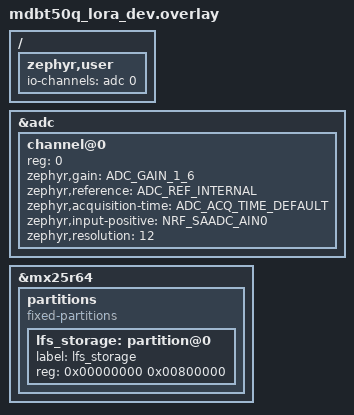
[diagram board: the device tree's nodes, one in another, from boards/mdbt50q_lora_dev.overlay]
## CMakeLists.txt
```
cmake_minimum_required(VERSION 3.20.0)

find_package(Zephyr REQUIRED HINTS $ENV{ZEPHYR_BASE})
project(6sens_rtos_store)

FILE(GLOB app_sources src/*.c)
target_sources(app PRIVATE ${app_sources})
```

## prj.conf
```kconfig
# Debugger Support
CONFIG_UART_CONSOLE=n
CONFIG_CONSOLE=y
CONFIG_SERIAL=y

# RTT Segger Support
CONFIG_RTT_CONSOLE=y
CONFIG_USE_SEGGER_RTT=y
CONFIG_LOG_BACKEND_RTT=y

# Communication Bus Support
CONFIG_GPIO=y
CONFIG_SPI=y

# Hardware Support
CONFIG_ADC=y
CONFIG_RING_BUFFER=y

# Flash Memory Support (MX25R64)
CONFIG_FLASH=y
CONFIG_FLASH_MAP=y
CONFIG_MPU_ALLOW_FLASH_WRITE=y
CONFIG_NORDIC_QSPI_NOR=y

# File System Support
CONFIG_FILE_SYSTEM=y
CONFIG_FILE_SYSTEM_LITTLEFS=y

# Threads Support
CONFIG_MAIN_STACK_SIZE=4096

# Utils
CONFIG_BASE64=y
```

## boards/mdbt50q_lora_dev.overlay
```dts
/*
 * Copyright (c) 2025
 * Regis Rousseau
 * Univ Lyon, INSA Lyon, Inria, CITI, EA3720
 * SPDX-License-Identifier: Apache-2.0
 */

/* Sismic sensor analog value conversion */
/* external ADC channnel of MDBT50Q, Port P0.02 on schematic */
/ {
	zephyr,user {
		io-channels = <&adc 0>;
	};
};

/* enable the corresponding ADC, with the correct configuration */
&adc {
	#address-cells	= <1>;
	#size-cells 	= <0>;
	status			= "okay";
	channel@0 {
		reg 					= <0>;						/* channel 0 of the ADC */
		zephyr,gain				= "ADC_GAIN_1_6";			/* attenuated by 6 (x1/6) */
		zephyr,reference		= "ADC_REF_INTERNAL";		/* reference voltage +0.6 */
		zephyr,acquisition-time = <ADC_ACQ_TIME_DEFAULT>;	/* 10us */
		zephyr,input-positive	= <NRF_SAADC_AIN0>;			/* P0.02 for nRF52xx */
		zephyr,resolution		= <12>;
	};
};

&mx25r64 {
	partitions {
		compatible		= "fixed-partitions";
		#address-cells	= <1>;
		#size-cells		= <1>;

		lfs_storage: partition@0 {
			label	= "lfs_storage";
			reg		= <0x00000000 0x00800000>;
		};
	};
};
```

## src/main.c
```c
/*
 * Copyright (c) 2025
 * Regis Rousseau
 * Univ Lyon, INSA Lyon, Inria, CITI, EA3720
 * SPDX-License-Identifier: Apache-2.0
 */

//  ========== includes ====================================================================
#include "app_adc.h"
#include "app_storage.h"
#include "fs_utils.h"

//  ========== defines =====================================================================
#define STACK_SIZE 					4096
#define ADC_THREAD_PRIORITY 		2
#define STORAGE_THREAD_PRIORITY		3
RING_BUF_DECLARE(adc_ringbuf, BUFFER_SIZE_SAMPLES * SAMPLE_SIZE_BYTES);

//  ========== globals =====================================================================
K_THREAD_STACK_DEFINE(adc_stack, STACK_SIZE);
K_THREAD_STACK_DEFINE(storage_stack, STACK_SIZE);

static struct k_thread adc_thread_data;
static struct k_thread storage_thread_data;

// ========== main =========================================================================
int main(void)
{	
	// initialize ADC device
	int8_t ret = app_nrf52_adc_init();
	if (ret != 1) {
		printk("failed to initialize ADC device\n");
		return 0;
	}

	printk("Geophone Acquisition Example\n");
	
	int rc = mount_lfs();
	if (rc < 0) {
        printk("mount failed. stopping application: %d\n", rc);
        return rc;
    }
	int clean_fs = false;
	// Dump the content of /lfs filesystem
	dump_fs(clean_fs);
    // start threads
    k_thread_create(&adc_thread_data, adc_stack, STACK_SIZE,
                    (k_thread_entry_t)app_nrf52_adc_thread, NULL, NULL, NULL,
                    ADC_THREAD_PRIORITY, 0, K_NO_WAIT);

    k_thread_create(&storage_thread_data, storage_stack, STACK_SIZE,
                    (k_thread_entry_t)app_storage_thread, NULL, NULL, NULL,
                    STORAGE_THREAD_PRIORITY, 0, K_NO_WAIT);

	while (1) {
        k_sleep(K_SECONDS(5));
	}
	return 0;
}
```

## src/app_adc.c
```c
/*
 * Copyright (c) 2025
 * Regis Rousseau
 * Univ Lyon, INSA Lyon, Inria, CITI, EA3720
 * SPDX-License-Identifier: Apache-2.0
 */

//  ========== includes ====================================================================
#include "app_adc.h"

//  ========== globals =====================================================================
// ADC buffer to store raw ADC readings
int16_t buf;

// ADC channel configuration obtained from the device tree
static const struct adc_dt_spec adc_channel = ADC_DT_SPEC_GET(DT_PATH(zephyr_user));

// ADC sequence configuration to specify the ADC operation
static struct adc_sequence sequence = {
    .channels = 0,
	.buffer = &buf,
	.buffer_size = sizeof(buf),
};

//  ========== app_nrf52_adc_init ==========================================================
int8_t app_nrf52_adc_init()
{
    int8_t ret;

    // verify if the ADC is ready for operation
    if (!adc_is_ready_dt(&adc_channel)) {
		printk("ADC is not ready\n");
		return 0;
    }
    
    // configure the ADC channel settings
    ret = adc_channel_setup_dt(&adc_channel);
	if (ret < 0) {
		printk("failed to set up ADC channel. error: %d\n", ret);
		return 0;
	}

    // initialize the ADC sequence for continuous or single readings
    ret = adc_sequence_init_dt(&adc_channel, &sequence);
	if (ret < 0) {
		printk("failed to initialize ADC sequence. error: %d\n", ret);
		return 0;
	}
    return 1;
}

//  ========== app_nrf52_get_adc ===========================================================
int16_t app_nrf52_adc_get()
{
    int16_t velocity;       // converted voltage value in mV
    int8_t ret;
    
    // trigger an ADC read and store the result in the configured buffer
    ret = adc_read(adc_channel.dev, &sequence);
    if (ret < 0) {        
	    printk("failed to read raw ADC value. error: %d\n", ret);
	    return 0;
    }

    //printk("raw adc value: %d\n", buf);

    // convert the raw ADC reading into a voltage value (in millivolts)
    velocity = (buf * ADC_FULL_SCALE_MV) / ADC_RESOLUTION;
    //printk("velocity: %d mV\n", velocity);
    return (int16_t)velocity;
}

//  ========== app_nrf52_adc_thread ========================================================
void app_nrf52_adc_thread(void *a, void *b, void *c)
{
    uint64_t next = k_uptime_get();
    
    while (1) {
        int16_t sample = app_nrf52_adc_get();

        uint32_t written = ring_buf_put(&adc_ringbuf, (uint8_t *)&sample, sizeof(sample));
           if (written < sizeof(sample)) {
            //printk("ring buffer full, dropping sample\n");
        }

        next += SAMPLE_RATE_MS;
        int64_t now = k_uptime_get();
        if (next > now) {
            k_sleep(K_MSEC(next - now));
        } else {
            next = now;
        }
    }
}
```

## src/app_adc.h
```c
/*
 * Copyright (c) 2025
 * Regis Rousseau
 * Univ Lyon, INSA Lyon, Inria, CITI, EA3720
 * SPDX-License-Identifier: Apache-2.0
 */

#ifndef APP_ADC_H
#define APP_ADC_H

//  ========== includes ====================================================================
#include <zephyr/kernel.h>
#include <zephyr/device.h>
#include <zephyr/devicetree.h>
#include <zephyr/drivers/adc.h>
#include <zephyr/sys/ring_buffer.h> 

//  ========== defines =====================================================================
// ADC characteristics (nRF52 SAADC)
#define ADC_REF_INTERNAL_MV         600     // 0.6 V internal reference
#define ADC_GAIN                    6       // using ADC_GAIN_1_6 -> 1/6
#define ADC_RESOLUTION              4096    // 12-bit

// effective full-scale voltage in mV
#define ADC_FULL_SCALE_MV   ((ADC_REF_INTERNAL_MV * ADC_GAIN))  // 3600 mV full scale

#define SAMPLE_RATE_MS              10
#define BUFFER_SIZE_SAMPLES         512
#define SAMPLE_SIZE_BYTES           sizeof(int16_t)

//  ========== globals =====================================================================
extern struct ring_buf adc_ringbuf;

//  ========== prototypes ==================================================================
int8_t app_nrf52_adc_init();
int16_t app_nrf52_adc_get();
void app_nrf52_adc_thread();

#endif /* APP_ADC_H */
```

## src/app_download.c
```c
/*
 * Copyright (c) 2025
 * Hugo Reymond, Regis Rousseau
 * Univ Lyon, INSA Lyon, Inria, CITI, EA3720
 * SPDX-License-Identifier: Apache-2.0
 */
#include "app_download.h"
#include <zephyr/sys/base64.h>
//  ========== globals =====================================================================
char ram_buffer[DOWNLOAD_RAM_BUF_SIZE];

//  ========== setup_download() ============================================================
void setup_download()
{
    int not_found = 1;
    int rc = 0;

    // Check if flash has been mounted
    while (not_found)
    {
        int mount_index = 0;
        char name[30];
        char *new_name = name;
        rc = 0;
        while (rc == 0)
        {
            rc = fs_readmount(&mount_index, &new_name);
            if (new_name[0] != 0)
            {
                printk("Found mount : %s\n", new_name);
            }
            if (new_name[0] == '/' && new_name[1] == 'l' && new_name[2] == 'f' && new_name[3] == 's')
            {
                printk("LFS mount is here !\n");
                not_found = 0;
            }
        }
        if (not_found)
        {
            printk("LFS mount not found,  sleeping...\n");
            k_sleep(K_SECONDS(1));
        }
    }

    // Get the lfs folder
    struct fs_dir_t root_dir;
    fs_dir_t_init(&root_dir);
    rc = fs_opendir(&root_dir, "/lfs");
    switch (rc)
    {
    case -EINVAL:
        printk("Bad directory given...\n");
        break;
    case 0:
        printk("Opened root folder\n");
    default:
        break;
        printk("Error : error code=%d\n", rc);
    }

    printk("Reading content of lfs dir\n");
    struct fs_dirent dir_entry;
    while (true)
    {
        rc = fs_readdir(&root_dir, &dir_entry);
        if (dir_entry.name[0] == 0 || rc < 0)
        {
            break;
        }
        printk("FILE:%s\n", dir_entry.name);
        
        char file_path[32];
        snprintf(file_path, sizeof(file_path), "%s%s", "/lfs/", dir_entry.name);

        dump_file(file_path);
        printk("File dumped !\n");
    }
}

void dump_file(char * file_path)
{   
    int rc;
    char * buffer[100] = {0};
    char * base64_encoded[200] = {0};
    // printf("Opening file %s\n", file_path);
    struct fs_file_t file;
    fs_file_t_init(&file);
    rc = fs_open(&file, file_path, FS_O_READ);
    if (rc < 0)
    {
        printk("file open failed. error: %d\n", rc);
        return;
    }
    
    int total_encoded = 0;
    int written = 1;
    while(written > 0) {
        printk("D:");
        written = fs_read(&file, buffer, 100);
        size_t encoded = 0;
        rc = base64_encode(base64_encoded, 200, &encoded, buffer, written);
        base64_encoded[encoded] = 0;
        if(rc != 0) {
            printf("Error encoding to base 64\n");
            return;
        }
        printk(base64_encoded);
        total_encoded += encoded;
        printk("\n");
        k_sleep(K_MSEC(15));
    }

    printk("TOTAL_ENCODED:%d", total_encoded);
    
    rc = fs_close(&file);
    if (rc < 0)
    {
        printk("file closed failed. error: %d\n", rc);
    }
    return;
}
```

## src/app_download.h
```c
/*
 * Copyright (c) 2025
 * Hugo Reymond, Regis Rousseau
 * Univ Lyon, INSA Lyon, Inria, CITI, EA3720
 * SPDX-License-Identifier: Apache-2.0
 */
#ifndef APP_DOWLOAD_H
#define APP_DOWLOAD_H

//  ========== includes ====================================================================
#include <zephyr/fs/fs.h>
#include <zephyr/fs/littlefs.h>


//  ========== defines =====================================================================
#define DOWNLOAD_RAM_BUF_SIZE 1024  

//  ========== prototypes ==================================================================
void setup_download();
void dump_file(char * file_path);


#endif // APP_DOWNLOAD_H
```

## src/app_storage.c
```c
/*
 * Copyright (c) 2025
 * Regis Rousseau
 * Univ Lyon, INSA Lyon, Inria, CITI, EA3720
 * SPDX-License-Identifier: Apache-2.0
 */

//  ========== includes ====================================================================
#include "app_storage.h"

//  ========== app_storage_thread ==========================================================
void app_storage_thread(void *arg1, void *arg2, void *arg3)
{
    struct fs_file_t file;
    fs_file_t_init(&file);

    static int file_index = 0;
    char file_path[32];
    snprintf(file_path, sizeof(file_path), "%s_%03d%s", FILE_PREFIX, file_index, FILE_EXT);

    int rc;    
    rc = fs_open(&file, file_path, FS_O_CREATE | FS_O_WRITE | FS_O_APPEND);
    if (rc < 0) {
        printk("file open failed. error: %d\n", rc);
        return;
    }
    // printf("\npartition address beginning: flash erase page at 0x%x\n", TEST_PARTITION_OFFSET);

    size_t current_file_size = fs_tell(&file);
    uint8_t buf[STORAGE_BUFFER_SIZE];

    while (1) {
        // pull data from ring buffer
        uint32_t len = ring_buf_get(&adc_ringbuf, buf, sizeof(buf));
        if (len > 0) {
            //printk("writing %u bytes\n", len);
            rc = fs_write(&file, buf, len);
            if (rc < 0) {
                printk("flash write failed. error: %d\n", rc);
            } else {
                current_file_size += len;
                //printk("current size: %zu / %d\n", current_file_size, MAX_FILE_SIZE);
            }

            // rotate file if max size reached
            if (current_file_size >= MAX_FILE_SIZE) {
                fs_close(&file);
                file_index++;
                snprintf(file_path, sizeof(file_path), "%s_%03d%s", FILE_PREFIX, file_index, FILE_EXT);
                fs_file_t_init(&file);
                rc = fs_open(&file, file_path, FS_O_CREATE | FS_O_WRITE | FS_O_APPEND);
                if (rc < 0) {
                    printk("failed to open new file. error: %d\n", rc);
                    return;
                }
                current_file_size = 0;
                printk("rotated to new file: %s\n", file_path);
            }
        } else {
            k_sleep(K_MSEC(5));
        }
    }

    fs_close(&file);
}
```

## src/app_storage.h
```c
/*
 * Copyright (c) 2025
 * Regis Rousseau
 * Univ Lyon, INSA Lyon, Inria, CITI, EA3720
 * SPDX-License-Identifier: Apache-2.0
 */

#ifndef APP_STORAGE_H
#define APP_STORAGE_H

//  ========== includes ====================================================================
#include "app_adc.h"
#include "fs_utils.h"
#include <zephyr/kernel.h>
#include <zephyr/device.h>
#include <zephyr/devicetree.h>
#include <zephyr/fs/fs.h>
#include <zephyr/fs/littlefs.h>
#include <zephyr/storage/flash_map.h>
#include <zephyr/sys/ring_buffer.h>

//  ========== prototypes ==================================================================
void app_storage_thread();

#endif /* APP_STORAGE_H */
```
